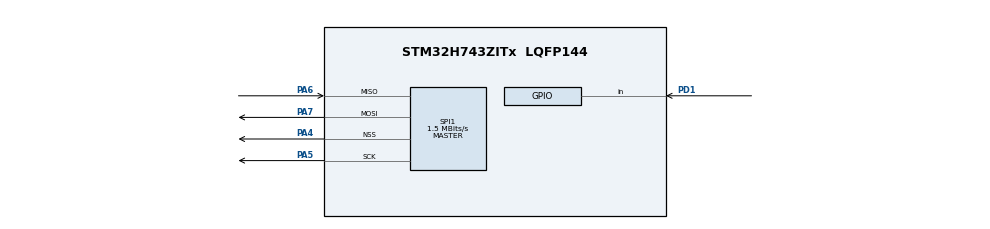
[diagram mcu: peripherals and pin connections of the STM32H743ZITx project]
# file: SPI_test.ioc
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CORTEX_M7.default_mode_Activation=1
Mcu.Family=STM32H7
Mcu.Name=STM32H743ZITx
Mcu.Package=LQFP144
NVIC.PriorityGroup=NVIC_PRIORITYGROUP_4
PA4.Mode=NSS_Signal_Hard_Output
PA4.Signal=SPI1_NSS
PA5.Mode=Full_Duplex_Master
PA5.Signal=SPI1_SCK
PA6.Mode=Full_Duplex_Master
PA6.Signal=SPI1_MISO
PA7.Mode=Full_Duplex_Master
PA7.Signal=SPI1_MOSI
PD1.Signal=GPIO_Input
PH0-OSC_IN\ (PH0).Mode=HSE-External-Oscillator
PH0-OSC_IN\ (PH0).Signal=RCC_OSC_IN
PH1-OSC_OUT\ (PH1).Mode=HSE-External-Oscillator
PH1-OSC_OUT\ (PH1).Signal=RCC_OSC_OUT
ProjectManager.HeapSize=0x200
ProjectManager.StackSize=0x400
ProjectManager.TargetToolchain=STM32CubeIDE
RCC.ADCFreq_Value=10000000
RCC.APB1Freq_Value=120000000
RCC.APB2Freq_Value=120000000
RCC.APB3Freq_Value=120000000
RCC.APB4Freq_Value=120000000
RCC.CortexFreq_Value=480000000
RCC.D1PPRE=RCC_APB3_DIV2
RCC.D2PPRE1=RCC_APB1_DIV2
RCC.D2PPRE2=RCC_APB2_DIV2
RCC.D3PPRE=RCC_APB4_DIV2
RCC.DIVM1=4
RCC.DIVM2=4
RCC.DIVN1=60
RCC.DIVN2=9
RCC.DIVP2=15
RCC.DIVQ1=5
RCC.HCLKFreq_Value=240000000
RCC.HPRE=RCC_HCLK_DIV2
RCC.HSE_VALUE=8000000
RCC.PLL2FRACN=3072
RCC.PLL3FRACN=0
RCC.PLLFRACN=0
RCC.SYSCLKFreq_VALUE=480000000
RCC.SYSCLKSource=RCC_SYSCLKSOURCE_PLLCLK
RCC.USBFreq_Value=192000000
SPI1.BaudRatePrescaler=SPI_BAUDRATEPRESCALER_128
SPI1.CalculateBaudRate=1.5 MBits/s
SPI1.DataSize=SPI_DATASIZE_8BIT
SPI1.Direction=SPI_DIRECTION_2LINES
SPI1.Mode=SPI_MODE_MASTER
SPI1.NSSPMode=SPI_NSS_PULSE_DISABLE
SPI1.VirtualNSS=VM_NSSHARD
SPI1.VirtualType=VM_MASTER
VP_MEMORYMAP_VS_MEMORYMAP.Mode=CurAppReg
board=custom

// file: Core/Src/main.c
/* USER CODE BEGIN Header */
/**
  ******************************************************************************
  * @file           : main.c
  * @brief          : Main program body
  ******************************************************************************
  * @attention
  *
  * Copyright (c) 2026 STMicroelectronics.
  * All rights reserved.
  *
  * This software is licensed under terms that can be found in the LICENSE file
  * in the root directory of this software component.
  * If no LICENSE file comes with this software, it is provided AS-IS.
  *
  ******************************************************************************
  */
/* USER CODE END Header */
#include "main.h"

SPI_HandleTypeDef hspi1;

/* USER CODE BEGIN PV */

uint8_t txData[4] = {'a','b','c','d'};
GPIO_PinState lastPD1 = GPIO_PIN_RESET;
/* USER CODE END PV */

void SystemClock_Config(void);
static void MPU_Config(void);
static void MX_GPIO_Init(void);
static void MX_SPI1_Init(void);

int main(void)
{

  /* MPU Configuration--------------------------------------------------------*/
  MPU_Config();

  /* MCU Configuration--------------------------------------------------------*/

  /* Reset of all peripherals, Initializes the Flash interface and the Systick. */
  HAL_Init();

  /* Configure the system clock */
  SystemClock_Config();

  /* Initialize all configured peripherals */
  MX_GPIO_Init();
  MX_SPI1_Init();

  /* Infinite loop */
  while (1)
  {

    /* USER CODE BEGIN 3 */
	  GPIO_PinState currentPD1 = HAL_GPIO_ReadPin(GPIOD, GPIO_PIN_1);

	  if ((lastPD1 == GPIO_PIN_RESET) && (currentPD1 == GPIO_PIN_SET))
	  {
	      // ตรวจพบขอบขาขึ้น (Low -> High)
	      HAL_SPI_Transmit(&hspi1, txData, 4, HAL_MAX_DELAY);
	  }

	  lastPD1 = currentPD1;
	 /* USER CODE END 3 */
  }

}

void SystemClock_Config(void)
{
  RCC_OscInitTypeDef RCC_OscInitStruct = {0};
  RCC_ClkInitTypeDef RCC_ClkInitStruct = {0};

  /** Supply configuration update enable
  */
  HAL_PWREx_ConfigSupply(PWR_LDO_SUPPLY);

  /** Configure the main internal regulator output voltage
  */
  __HAL_PWR_VOLTAGESCALING_CONFIG(PWR_REGULATOR_VOLTAGE_SCALE0);

  while(!__HAL_PWR_GET_FLAG(PWR_FLAG_VOSRDY)) {}

  /** Initializes the RCC Oscillators according to the specified parameters
  * in the RCC_OscInitTypeDef structure.
  */
  RCC_OscInitStruct.OscillatorType = RCC_OSCILLATORTYPE_HSI;
  RCC_OscInitStruct.HSIState = RCC_HSI_DIV1;
  RCC_OscInitStruct.HSICalibrationValue = RCC_HSICALIBRATION_DEFAULT;
  RCC_OscInitStruct.PLL.PLLState = RCC_PLL_ON;
  RCC_OscInitStruct.PLL.PLLSource = RCC_PLLSOURCE_HSI;
  RCC_OscInitStruct.PLL.PLLM = 4;
  RCC_OscInitStruct.PLL.PLLN = 60;
  RCC_OscInitStruct.PLL.PLLP = 2;
  RCC_OscInitStruct.PLL.PLLQ = 5;
  RCC_OscInitStruct.PLL.PLLR = 2;
  RCC_OscInitStruct.PLL.PLLRGE = RCC_PLL1VCIRANGE_3;
  RCC_OscInitStruct.PLL.PLLVCOSEL = RCC_PLL1VCOWIDE;
  RCC_OscInitStruct.PLL.PLLFRACN = 0;
  if (HAL_RCC_OscConfig(&RCC_OscInitStruct) != HAL_OK)
  {
    Error_Handler();
  }

  /** Initializes the CPU, AHB and APB buses clocks
  */
  RCC_ClkInitStruct.ClockType = RCC_CLOCKTYPE_HCLK|RCC_CLOCKTYPE_SYSCLK
                              |RCC_CLOCKTYPE_PCLK1|RCC_CLOCKTYPE_PCLK2
                              |RCC_CLOCKTYPE_D3PCLK1|RCC_CLOCKTYPE_D1PCLK1;
  RCC_ClkInitStruct.SYSCLKSource = RCC_SYSCLKSOURCE_PLLCLK;
  RCC_ClkInitStruct.SYSCLKDivider = RCC_SYSCLK_DIV1;
  RCC_ClkInitStruct.AHBCLKDivider = RCC_HCLK_DIV2;
  RCC_ClkInitStruct.APB3CLKDivider = RCC_APB3_DIV2;
  RCC_ClkInitStruct.APB1CLKDivider = RCC_APB1_DIV2;
  RCC_ClkInitStruct.APB2CLKDivider = RCC_APB2_DIV2;
  RCC_ClkInitStruct.APB4CLKDivider = RCC_APB4_DIV2;

  if (HAL_RCC_ClockConfig(&RCC_ClkInitStruct, FLASH_LATENCY_4) != HAL_OK)
  {
    Error_Handler();
  }
}

static void MX_SPI1_Init(void)
{

  /* SPI1 parameter configuration*/
  hspi1.Instance = SPI1;
  hspi1.Init.Mode = SPI_MODE_MASTER;
  hspi1.Init.Direction = SPI_DIRECTION_2LINES;
  hspi1.Init.DataSize = SPI_DATASIZE_8BIT;
  hspi1.Init.CLKPolarity = SPI_POLARITY_LOW;
  hspi1.Init.CLKPhase = SPI_PHASE_1EDGE;
  hspi1.Init.NSS = SPI_NSS_HARD_OUTPUT;
  hspi1.Init.BaudRatePrescaler = SPI_BAUDRATEPRESCALER_128;
  hspi1.Init.FirstBit = SPI_FIRSTBIT_MSB;
  hspi1.Init.TIMode = SPI_TIMODE_DISABLE;
  hspi1.Init.CRCCalculation = SPI_CRCCALCULATION_DISABLE;
  hspi1.Init.CRCPolynomial = 0x0;
  hspi1.Init.NSSPMode = SPI_NSS_PULSE_DISABLE;
  hspi1.Init.NSSPolarity = SPI_NSS_POLARITY_LOW;
  hspi1.Init.FifoThreshold = SPI_FIFO_THRESHOLD_01DATA;
  hspi1.Init.TxCRCInitializationPattern = SPI_CRC_INITIALIZATION_ALL_ZERO_PATTERN;
  hspi1.Init.RxCRCInitializationPattern = SPI_CRC_INITIALIZATION_ALL_ZERO_PATTERN;
  hspi1.Init.MasterSSIdleness = SPI_MASTER_SS_IDLENESS_00CYCLE;
  hspi1.Init.MasterInterDataIdleness = SPI_MASTER_INTERDATA_IDLENESS_00CYCLE;
  hspi1.Init.MasterReceiverAutoSusp = SPI_MASTER_RX_AUTOSUSP_DISABLE;
  hspi1.Init.MasterKeepIOState = SPI_MASTER_KEEP_IO_STATE_DISABLE;
  hspi1.Init.IOSwap = SPI_IO_SWAP_DISABLE;
  if (HAL_SPI_Init(&hspi1) != HAL_OK)
  {
    Error_Handler();
  }

}

static void MX_GPIO_Init(void)
{
  GPIO_InitTypeDef GPIO_InitStruct = {0};

  /* GPIO Ports Clock Enable */
  __HAL_RCC_GPIOH_CLK_ENABLE();
  __HAL_RCC_GPIOA_CLK_ENABLE();
  __HAL_RCC_GPIOD_CLK_ENABLE();

  /*Configure GPIO pin : PD1 */
  GPIO_InitStruct.Pin = GPIO_PIN_1;
  GPIO_InitStruct.Mode = GPIO_MODE_INPUT;
  GPIO_InitStruct.Pull = GPIO_NOPULL;
  HAL_GPIO_Init(GPIOD, &GPIO_InitStruct);

}

 /* MPU Configuration */

void MPU_Config(void)
{
  MPU_Region_InitTypeDef MPU_InitStruct = {0};

  /* Disables the MPU */
  HAL_MPU_Disable();

  /** Initializes and configures the Region and the memory to be protected
  */
  MPU_InitStruct.Enable = MPU_REGION_ENABLE;
  MPU_InitStruct.Number = MPU_REGION_NUMBER0;
  MPU_InitStruct.BaseAddress = 0x0;
  MPU_InitStruct.Size = MPU_REGION_SIZE_4GB;
  MPU_InitStruct.SubRegionDisable = 0x87;
  MPU_InitStruct.TypeExtField = MPU_TEX_LEVEL0;
  MPU_InitStruct.AccessPermission = MPU_REGION_NO_ACCESS;
  MPU_InitStruct.DisableExec = MPU_INSTRUCTION_ACCESS_DISABLE;
  MPU_InitStruct.IsShareable = MPU_ACCESS_SHAREABLE;
  MPU_InitStruct.IsCacheable = MPU_ACCESS_NOT_CACHEABLE;
  MPU_InitStruct.IsBufferable = MPU_ACCESS_NOT_BUFFERABLE;

  HAL_MPU_ConfigRegion(&MPU_InitStruct);
  /* Enables the MPU */
  HAL_MPU_Enable(MPU_PRIVILEGED_DEFAULT);

}

void Error_Handler(void)
{
  __disable_irq();
  while (1)
  {
  }
}
